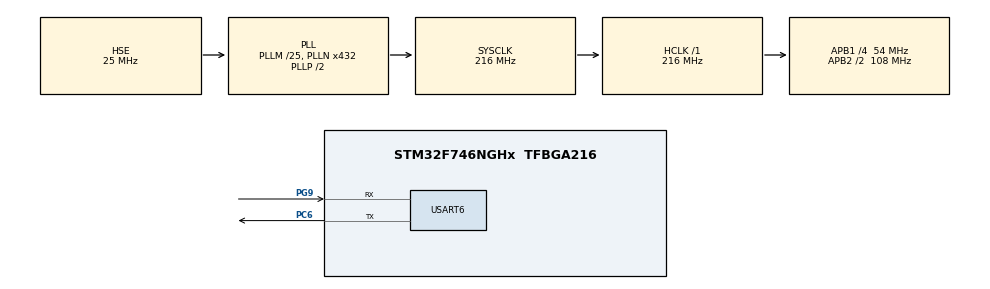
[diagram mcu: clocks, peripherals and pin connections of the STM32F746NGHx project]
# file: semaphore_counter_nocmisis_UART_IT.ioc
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FREERTOS.Tasks01=defaultTask,0,128,StartDefaultTask,Default,NULL,Dynamic,NULL,NULL
FREERTOS.configUSE_COUNTING_SEMAPHORES=1
Mcu.Family=STM32F7
Mcu.Name=STM32F746NGHx
Mcu.Package=TFBGA216
NVIC.PriorityGroup=NVIC_PRIORITYGROUP_4
NVIC.TIM1_UP_TIM10_IRQn=true\:15\:0\:false\:false\:true\:false\:false\:true\:true
NVIC.TimeBase=TIM1_UP_TIM10_IRQn
NVIC.TimeBaseIP=TIM1
NVIC.USART6_IRQn=true\:5\:0\:false\:false\:true\:true\:true\:true\:true
PC6.Mode=Asynchronous
PC6.Signal=USART6_TX
PG9.Mode=Asynchronous
PG9.Signal=USART6_RX
PH0/OSC_IN.Mode=HSE-External-Oscillator
PH0/OSC_IN.Signal=RCC_OSC_IN
PH1/OSC_OUT.Mode=HSE-External-Oscillator
PH1/OSC_OUT.Signal=RCC_OSC_OUT
ProjectManager.HeapSize=0x200
ProjectManager.StackSize=0x400
ProjectManager.TargetToolchain=STM32CubeIDE
RCC.AHBFreq_Value=216000000
RCC.APB1CLKDivider=RCC_HCLK_DIV4
RCC.APB1Freq_Value=54000000
RCC.APB1TimFreq_Value=108000000
RCC.APB2CLKDivider=RCC_HCLK_DIV2
RCC.APB2Freq_Value=108000000
RCC.APB2TimFreq_Value=216000000
RCC.CortexFreq_Value=216000000
RCC.HCLKFreq_Value=216000000
RCC.HSE_VALUE=25000000
RCC.HSI_VALUE=16000000
RCC.PLL48CLockSelection=RCC_CLK48SOURCE_PLLSAIP
RCC.PLLI2SN=100
RCC.PLLM=25
RCC.PLLN=432
RCC.PLLQ=9
RCC.PLLSAIN=384
RCC.PLLSAIP=RCC_PLLSAIP_DIV8
RCC.PLLSAIR=5
RCC.PLLSAIRDiv=RCC_PLLSAIDIVR_8
RCC.PLLSourceVirtual=RCC_PLLSOURCE_HSE
RCC.SDMMCClockSelection=RCC_SDMMC1CLKSOURCE_CLK48
RCC.SYSCLKFreq_VALUE=216000000
RCC.SYSCLKSource=RCC_SYSCLKSOURCE_PLLCLK
RCC.USBFreq_Value=48000000
RCC.VCOOutputFreq_Value=432000000
USART6.VirtualMode-Asynchronous=VM_ASYNC
VP_FREERTOS_VS_CMSIS_V1.Mode=CMSIS_V1
VP_SYS_VS_tim1.Mode=TIM1
board=STM32F746G-DISCO

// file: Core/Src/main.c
/* USER CODE BEGIN Header */
/**
  ******************************************************************************
  * @file           : main.c
  * @brief          : Main program body
  ******************************************************************************
  * @attention
  *
  * Copyright (c) 2025 STMicroelectronics.
  * All rights reserved.
  *
  * This software is licensed under terms that can be found in the LICENSE file
  * in the root directory of this software component.
  * If no LICENSE file comes with this software, it is provided AS-IS.
  *
  ******************************************************************************
  */
/* USER CODE END Header */
#include "main.h"
//YT: ControllersTech
//Binary semaphore needs to be released by the task that hase acquired it, where as counting semaphore can be released anywhere
//#include "cmsis_os.h" <---------------------------------not used
/*| Prefix | Meaning                                    | Example                                 |
  | ------ | ------------------------------------------ | --------------------------------------- |
  | `x`    | **BaseType\_t** (int32\_t or int)          | `xTaskCreate()`, `xSemaphoreGive()`     |
  | `v`    | **void** return type                       | `vTaskDelay()`, `vTaskStartScheduler()` |
  | `pd`   | **Port-dependent value** (usually boolean) | `pdTRUE`, `pdFALSE`                     |
  | `ux`   | **Unsigned BaseType\_t**                   | `uxTaskPriorityGet()`                   |
  | `pv`   | **Pointer to void**                        | `pvPortMalloc()`                        |
  | `e`    | **Enum**                                   | `eRunning`, `eBlocked`                  |
 *
 *Many functions like xSemaphoreTake() or xQueueSend() return a status (pdTRUE or pdFALSE), and the x implies it's returning a BaseType_t, not void.
 *It’s a reminder to the developer: check the return value.
 *
 * */
/* USER CODE BEGIN Includes */
#include "FreeRTOS.h" //includes are from cmsis file: common microcomputer software interface standardftware
#include "task.h"
#include "timers.h"
#include "queue.h"
#include "semphr.h"
#include "event_groups.h"

#include "stdlib.h"
#include "string.h"
/* USER CODE END Includes */

UART_HandleTypeDef huart6;

void SystemClock_Config(void);
static void MX_GPIO_Init(void);
static void MX_USART6_UART_Init(void);

/* USER CODE BEGIN 0 */

//create task defines

TaskHandle_t HPThandler;
void HPT_TASK(void *pvParamaters);

TaskHandle_t MPThandler;
void MPT_TASK(void *pvParamaters);

TaskHandle_t LPThandler;
void LPT_TASK(void *pvParamaters);

TaskHandle_t VLPThandler;
void VLPT_TASK(void *pvParamaters);

//semaphore related
SemaphoreHandle_t CountingSem;

//resource related
int resource[3]= {111, 222, 333};
int indx = 0;

//uart related
uint8_t rx_data = 0;
/* USER CODE END 0 */

int main(void)
{

  /* MCU Configuration--------------------------------------------------------*/

  /* Reset of all peripherals, Initializes the Flash interface and the Systick. */
  HAL_Init();

  /* Configure the system clock */
  SystemClock_Config();

  /* Initialize all configured peripherals */
  MX_GPIO_Init();
  MX_USART6_UART_Init();
  /* USER CODE BEGIN 2 */
  HAL_UART_Receive_IT(&huart6, &rx_data, 1);
  CountingSem= xSemaphoreCreateCounting(3,0);
  if(CountingSem == NULL) HAL_UART_Transmit(&huart6, (uint8_t *) "Unable to create Semaphore \n \n ", 28, 100);
  else
  {
	  HAL_UART_Transmit(&huart6, (uint8_t *) "Counting Semaphore created successfully\n \n" , 41, 1000);
  }

  //create tasks
  xTaskCreate(HPT_TASK, "HPT", 128, NULL, 3, &HPThandler);
  xTaskCreate(MPT_TASK, "MPT", 128, NULL, 2, &MPThandler);
  xTaskCreate(LPT_TASK, "LPT", 128, NULL, 1, &LPThandler);
  xTaskCreate(VLPT_TASK,"VLPT",128, NULL, 0 , &VLPThandler);

  vTaskStartScheduler();
  /* USER CODE END 2 */

  /* We should never get here as control is now taken by the scheduler */

  /* Infinite loop */
  while (1)
  {

  }
}

void SystemClock_Config(void)
{
  RCC_OscInitTypeDef RCC_OscInitStruct = {0};
  RCC_ClkInitTypeDef RCC_ClkInitStruct = {0};

  /** Configure the main internal regulator output voltage
  */
  __HAL_RCC_PWR_CLK_ENABLE();
  __HAL_PWR_VOLTAGESCALING_CONFIG(PWR_REGULATOR_VOLTAGE_SCALE1);

  /** Initializes the RCC Oscillators according to the specified parameters
  * in the RCC_OscInitTypeDef structure.
  */
  RCC_OscInitStruct.OscillatorType = RCC_OSCILLATORTYPE_HSE;
  RCC_OscInitStruct.HSEState = RCC_HSE_ON;
  RCC_OscInitStruct.PLL.PLLState = RCC_PLL_ON;
  RCC_OscInitStruct.PLL.PLLSource = RCC_PLLSOURCE_HSE;
  RCC_OscInitStruct.PLL.PLLM = 25;
  RCC_OscInitStruct.PLL.PLLN = 432;
  RCC_OscInitStruct.PLL.PLLP = RCC_PLLP_DIV2;
  RCC_OscInitStruct.PLL.PLLQ = 9;
  if (HAL_RCC_OscConfig(&RCC_OscInitStruct) != HAL_OK)
  {
    Error_Handler();
  }

  /** Activate the Over-Drive mode
  */
  if (HAL_PWREx_EnableOverDrive() != HAL_OK)
  {
    Error_Handler();
  }

  /** Initializes the CPU, AHB and APB buses clocks
  */
  RCC_ClkInitStruct.ClockType = RCC_CLOCKTYPE_HCLK|RCC_CLOCKTYPE_SYSCLK
                              |RCC_CLOCKTYPE_PCLK1|RCC_CLOCKTYPE_PCLK2;
  RCC_ClkInitStruct.SYSCLKSource = RCC_SYSCLKSOURCE_PLLCLK;
  RCC_ClkInitStruct.AHBCLKDivider = RCC_SYSCLK_DIV1;
  RCC_ClkInitStruct.APB1CLKDivider = RCC_HCLK_DIV4;
  RCC_ClkInitStruct.APB2CLKDivider = RCC_HCLK_DIV2;

  if (HAL_RCC_ClockConfig(&RCC_ClkInitStruct, FLASH_LATENCY_7) != HAL_OK)
  {
    Error_Handler();
  }
}

static void MX_USART6_UART_Init(void)
{

  huart6.Instance = USART6;
  huart6.Init.BaudRate = 115200;
  huart6.Init.WordLength = UART_WORDLENGTH_8B;
  huart6.Init.StopBits = UART_STOPBITS_1;
  huart6.Init.Parity = UART_PARITY_NONE;
  huart6.Init.Mode = UART_MODE_TX_RX;
  huart6.Init.HwFlowCtl = UART_HWCONTROL_NONE;
  huart6.Init.OverSampling = UART_OVERSAMPLING_16;
  huart6.Init.OneBitSampling = UART_ONE_BIT_SAMPLE_DISABLE;
  huart6.AdvancedInit.AdvFeatureInit = UART_ADVFEATURE_NO_INIT;
  if (HAL_UART_Init(&huart6) != HAL_OK)
  {
    Error_Handler();
  }

}

static void MX_GPIO_Init(void)
{

  /* GPIO Ports Clock Enable */
  __HAL_RCC_GPIOG_CLK_ENABLE();
  __HAL_RCC_GPIOH_CLK_ENABLE();
  __HAL_RCC_GPIOC_CLK_ENABLE();

}

/* USER CODE BEGIN 4 */
void HPT_TASK ( void *pvParameters)
{
	char sresource[5];
	int semcount=0;
	char ssemcount[5];
	//Give 3 Semaphores at the beginning
	/*semaphores can be released in any part of the code*/
	xSemaphoreGive(CountingSem);
	xSemaphoreGive(CountingSem);
	xSemaphoreGive(CountingSem);

	while(1)
	{
		char str[300];
		strcpy(str, "\rEntered HPT Task\r\nAbout to ACQUIRE the semaphore\r\n\n");
		semcount = uxSemaphoreGetCount(CountingSem);
		itoa(semcount, ssemcount, 10);
		strcat(str, "Tokens available are: ");
		strcat(str, ssemcount);
		//strcat(str, "\n\n");
        HAL_UART_Transmit(&huart6, (uint8_t *)str, strlen(str), HAL_MAX_DELAY);

        // Acquire semaphore
        xSemaphoreTake(CountingSem, portMAX_DELAY);

        // Prepare second message
		itoa(resource[indx], sresource, 10);
		strcpy(str, "\r\nLeaving HPT Task\r\nData ACCESSED :: ");
		strcat(str, sresource);
		strcat(str, "\r\nNot releasing the Semaphore\r\n\n");

		HAL_UART_Transmit(&huart6, (uint8_t *)str, strlen(str), HAL_MAX_DELAY);

		indx++;
		if(indx>2) indx=0;
//		vTaskDelay(3000);
		vTaskDelete(NULL);
	}
}

void MPT_TASK ( void *pvParameters)
{
	char sresource[3];
	int semcount=0;
	char ssemcount[2];
	while(1)
	{
		char str[300];
		strcpy(str, "\r\nEntered MPT Task\r\nAbout to ACQUIRE the semaphore\r\n\n");
		semcount = uxSemaphoreGetCount(CountingSem);
		itoa(semcount, ssemcount, 10);
		strcat(str, "Tokens available are: ");
		strcat(str, ssemcount);
		//strcat(str, "\n\n");
		HAL_UART_Transmit(&huart6, (uint8_t *)str, strlen(str), HAL_MAX_DELAY);
		xSemaphoreTake(CountingSem, portMAX_DELAY);
		itoa(resource[indx], sresource, 10);
		strcpy(str, "\r\nLeaving MPT Task\n\rData ACCCESSED :: ");
		strcat(str, sresource);
		strcat(str, "\r\nNot releasing the Semaphore\r\n\n\n");
		HAL_UART_Transmit(&huart6, (uint8_t *)str, strlen(str), HAL_MAX_DELAY);

		indx++;
		if(indx>2) indx=0;
//		vTaskDelay(2000);
		vTaskDelete(NULL);
	}
}

void LPT_TASK ( void *pvParameters)
{
	char sresource[3];
	int semcount=0;
	char ssemcount[2];
	while(1)
	{
		char str[150];
		strcpy(str, "\r\nEntered LPT Task\r\nAbout to ACQUIRE the semaphore\r\n");
		semcount = uxSemaphoreGetCount(CountingSem);
		itoa(semcount, ssemcount, 10);
		strcat(str, "Tokens available are: ");
		strcat(str, ssemcount);
		//strcat(str, "\n\n");

		HAL_UART_Transmit(&huart6, (uint8_t *)str, strlen(str), HAL_MAX_DELAY);
		xSemaphoreTake(CountingSem, portMAX_DELAY);
		itoa(resource[indx], sresource, 10);
		strcpy(str, "\r\nLeaving LPT Task\r\n Data ACCCESSED :: ");
		strcat(str, sresource);
		strcat(str, "\r\nNot releasing the Semaphore\r\n\n\n");
		HAL_UART_Transmit(&huart6, (uint8_t *)str, strlen(str), HAL_MAX_DELAY);

		indx++;
		if(indx>2) indx=0;
//		vTaskDelay(1000);
		vTaskDelete(NULL);
	}
}

void VLPT_TASK ( void *pvParameters)
{
	char sresource[3];
	int semcount=0;
	char ssemcount[2];
	while(1)
	{
		char str[300];
		strcpy(str, "\r\nEntered VLPT Task\r\nAbout to ACQUIRE the semaphore\r\n\n");
		semcount = uxSemaphoreGetCount(CountingSem);
		itoa(semcount, ssemcount, 10);
		strcat(str, "Tokens available are: ");
		strcat(str, ssemcount);
		//strcat(str, "\n\n");

		HAL_UART_Transmit(&huart6, (uint8_t *)str, strlen(str), HAL_MAX_DELAY);
		xSemaphoreTake(CountingSem, portMAX_DELAY);
		itoa(resource[indx], sresource, 10);
		strcpy(str, "\r\nLeaving VLPT Task\nData ACCCESSED :: ");
		strcat(str, sresource);
		strcat(str, "\r\nNot releasing the Semaphore\r\n\n\n");
		HAL_UART_Transmit(&huart6, (uint8_t *)str, strlen(str), HAL_MAX_DELAY);
		indx++;
		if(indx>2) indx=0;
		vTaskDelay(500);

	}
}

void HAL_UART_RxCpltCallback(UART_HandleTypeDef *huart)
{
	HAL_UART_Receive_IT(huart, &rx_data, 1);
	if(rx_data == 'r')
	{
		//release semaphore data here
		/*The xHigherPriorityTaskWoken parameter must be initialized to pdFALSE as it will
		 * get set to pdTRUE inside the interrupt safe API function if a context switch is required*/
		BaseType_t xHigherPriorityTaskWoken = pdFALSE;
		xSemaphoreGiveFromISR(CountingSem, & xHigherPriorityTaskWoken); //ISR SAFE VERSION

		/*Pass the xHigherPriorityTaskWoken value into portEND_SWITCH_ISR(). If
		 xHigherPriorityTaskWoken was set to pdTRUE inside xSemaphoreGiveFromISR()
		 then calling portEND_SWITCHING_ISR() will have no effect*/

		portEND_SWITCHING_ISR(xHigherPriorityTaskWoken);
	}
}
/* USER CODE END 4 */

void HAL_TIM_PeriodElapsedCallback(TIM_HandleTypeDef *htim)
{
  if (htim->Instance == TIM1)
  {
    HAL_IncTick();
  }
}

void Error_Handler(void)
{
  __disable_irq();
  while (1)
  {
  }
}

//
///* USER CODE BEGIN Header */
///**
//  ******************************************************************************
//  * @file           : main.c
//  * @brief          : Main program body
//  ******************************************************************************
//  * @attention
//  *
//  * Copyright (c) 2025 STMicroelectronics.
//  * All rights reserved.
//  *
//  * This software is licensed under terms that can be found in the LICENSE file
//  * in the root directory of this software component.
//  * If no LICENSE file comes with this software, it is provided AS-IS.
//  *
//  ******************************************************************************
//  */
///* USER CODE END Header */
///* Includes ------------------------------------------------------------------*/
//#include "main.h"
////YT: ControllersTech
////#include "cmsis_os.h" <---------------------------------not used
///*| Prefix | Meaning                                    | Example                                 |
//  | ------ | ------------------------------------------ | --------------------------------------- |
//  | `x`    | **BaseType\_t** (int32\_t or int)          | `xTaskCreate()`, `xSemaphoreGive()`     |
//  | `v`    | **void** return type                       | `vTaskDelay()`, `vTaskStartScheduler()` |
//  | `pd`   | **Port-dependent value** (usually boolean) | `pdTRUE`, `pdFALSE`                     |
//  | `ux`   | **Unsigned BaseType\_t**                   | `uxTaskPriorityGet()`                   |
//  | `pv`   | **Pointer to void**                        | `pvPortMalloc()`                        |
//  | `e`    | **Enum**                                   | `eRunning`, `eBlocked`                  |
// *
// *Many functions like xSemaphoreTake() or xQueueSend() return a status (pdTRUE or pdFALSE), and the x implies it's returning a BaseType_t, not void.
// *It’s a reminder to the developer: check the return value.
// *
// * */
///* Private includes ----------------------------------------------------------*/
///* USER CODE BEGIN Includes */
//#include "FreeRTOS.h" //includes are from cmsis file: common microcomputer software interface standardftware
//#include "task.h"
//#include "timers.h"
//#include "queue.h"
//#include "semphr.h"
//#include "event_groups.h"
//
//
//#include "stdlib.h"
//#include "string.h"
///* USER CODE END Includes */
//
///* Private typedef -----------------------------------------------------------*/
///* USER CODE BEGIN PTD */
//
///* USER CODE END PTD */
//
///* Private define ------------------------------------------------------------*/
///* USER CODE BEGIN PD */
//
///* USER CODE END PD */
//
///* Private macro -------------------------------------------------------------*/
///* USER CODE BEGIN PM */
//
///* USER CODE END PM */
//
///* Private variables ---------------------------------------------------------*/
//
//UART_HandleTypeDef huart6;
//
///* USER CODE BEGIN PV */
//
///* USER CODE END PV */
//
///* Private function prototypes -----------------------------------------------*/
//void SystemClock_Config(void);
//static void MX_GPIO_Init(void);
//static void MX_USART6_UART_Init(void);
//
//
///* USER CODE BEGIN PFP */
//
///* USER CODE END PFP */
//
///* Private user code ---------------------------------------------------------*/
///* USER CODE BEGIN 0 */
//
////create task defines
//
//TaskHandle_t HPThandler;
//void HPT_TASK(void *pvParamaters);
//
//TaskHandle_t MPThandler;
//void MPT_TASK(void *pvParamaters);
//
//TaskHandle_t LPThandler;
//void LPT_TASK(void *pvParamaters);
//
//TaskHandle_t VLPThandler;
//void VLPT_TASK(void *pvParamaters);
//
////semaphore related
//SemaphoreHandle_t CountingSem;
//
////resource related
//int resource[3]= {111, 222, 333};
//int indx = 0;
//
////uart related
//uint8_t rx_data = 0;
///* USER CODE END 0 */
//
///**
//  * @brief  The application entry point.
//  * @retval int
//  */
//int main(void)
//{
//
//  /* USER CODE BEGIN 1 */
//
//  /* USER CODE END 1 */
//
//  /* MCU Configuration--------------------------------------------------------*/
//
//  /* Reset of all peripherals, Initializes the Flash interface and the Systick. */
//  HAL_Init();
//
//  /* USER CODE BEGIN Init */
//
//  /* USER CODE END Init */
//
//  /* Configure the system clock */
//  SystemClock_Config();
//
//  /* USER CODE BEGIN SysInit */
//
//  /* USER CODE END SysInit */
//
//  /* Initialize all configured peripherals */
//  MX_GPIO_Init();
//  MX_USART6_UART_Init();
//  /* USER CODE BEGIN 2 */
//  HAL_UART_Receive_IT(&huart6, &rx_data, 1);
//  CountingSem= xSemaphoreCreateCounting(3,0);
//  if(CountingSem == NULL) HAL_UART_Transmit(&huart6, (uint8_t *) "Unable to create Semaphore \n \n ", 28, 100);
//  else
//  {
//	  HAL_UART_Transmit(&huart6, (uint8_t *) "\r\nCounting Semaphore created successfully" , 41, 1000);
//  }
//
//  //create tasks
//  xTaskCreate(HPT_TASK, "HPT", 128, NULL, 3, &HPThandler);
//  xTaskCreate(MPT_TASK, "MPT", 128, NULL, 2, &MPThandler);
//  xTaskCreate(LPT_TASK, "LPT", 128, NULL, 1, &LPThandler);
//  xTaskCreate(VLPT_TASK,"VLPT",128, NULL, 0 , &VLPThandler);
//
//  vTaskStartScheduler();
//  /* USER CODE END 2 */
//
//
//
//
//  /* We should never get here as control is now taken by the scheduler */
//
//  /* Infinite loop */
//  /* USER CODE BEGIN WHILE */
//  while (1)
//  {
//    /* USER CODE END WHILE */
//
//    /* USER CODE BEGIN 3 */
//  }
//  /* USER CODE END 3 */
//}
//
///**
//  * @brief System Clock Configuration
//  * @retval None
//  */
//void SystemClock_Config(void)
//{
//  RCC_OscInitTypeDef RCC_OscInitStruct = {0};
//  RCC_ClkInitTypeDef RCC_ClkInitStruct = {0};
//
//  /** Configure the main internal regulator output voltage
//  */
//  __HAL_RCC_PWR_CLK_ENABLE();
//  __HAL_PWR_VOLTAGESCALING_CONFIG(PWR_REGULATOR_VOLTAGE_SCALE1);
//
//  /** Initializes the RCC Oscillators according to the specified parameters
//  * in the RCC_OscInitTypeDef structure.
//  */
//  RCC_OscInitStruct.OscillatorType = RCC_OSCILLATORTYPE_HSE;
//  RCC_OscInitStruct.HSEState = RCC_HSE_ON;
//  RCC_OscInitStruct.PLL.PLLState = RCC_PLL_ON;
//  RCC_OscInitStruct.PLL.PLLSource = RCC_PLLSOURCE_HSE;
//  RCC_OscInitStruct.PLL.PLLM = 25;
//  RCC_OscInitStruct.PLL.PLLN = 432;
//  RCC_OscInitStruct.PLL.PLLP = RCC_PLLP_DIV2;
//  RCC_OscInitStruct.PLL.PLLQ = 9;
//  if (HAL_RCC_OscConfig(&RCC_OscInitStruct) != HAL_OK)
//  {
//    Error_Handler();
//  }
//
//  /** Activate the Over-Drive mode
//  */
//  if (HAL_PWREx_EnableOverDrive() != HAL_OK)
//  {
//    Error_Handler();
//  }
//
//  /** Initializes the CPU, AHB and APB buses clocks
//  */
//  RCC_ClkInitStruct.ClockType = RCC_CLOCKTYPE_HCLK|RCC_CLOCKTYPE_SYSCLK
//                              |RCC_CLOCKTYPE_PCLK1|RCC_CLOCKTYPE_PCLK2;
//  RCC_ClkInitStruct.SYSCLKSource = RCC_SYSCLKSOURCE_PLLCLK;
//  RCC_ClkInitStruct.AHBCLKDivider = RCC_SYSCLK_DIV1;
//  RCC_ClkInitStruct.APB1CLKDivider = RCC_HCLK_DIV4;
//  RCC_ClkInitStruct.APB2CLKDivider = RCC_HCLK_DIV2;
//
//  if (HAL_RCC_ClockConfig(&RCC_ClkInitStruct, FLASH_LATENCY_7) != HAL_OK)
//  {
//    Error_Handler();
//  }
//}
//
///**
//  * @brief USART6 Initialization Function
//  * @param None
//  * @retval None
//  */
//static void MX_USART6_UART_Init(void)
//{
//
//  /* USER CODE BEGIN USART6_Init 0 */
//
//  /* USER CODE END USART6_Init 0 */
//
//  /* USER CODE BEGIN USART6_Init 1 */
//
//  /* USER CODE END USART6_Init 1 */
//  huart6.Instance = USART6;
//  huart6.Init.BaudRate = 115200;
//  huart6.Init.WordLength = UART_WORDLENGTH_8B;
//  huart6.Init.StopBits = UART_STOPBITS_1;
//  huart6.Init.Parity = UART_PARITY_NONE;
//  huart6.Init.Mode = UART_MODE_TX_RX;
//  huart6.Init.HwFlowCtl = UART_HWCONTROL_NONE;
//  huart6.Init.OverSampling = UART_OVERSAMPLING_16;
//  huart6.Init.OneBitSampling = UART_ONE_BIT_SAMPLE_DISABLE;
//  huart6.AdvancedInit.AdvFeatureInit = UART_ADVFEATURE_NO_INIT;
//  if (HAL_UART_Init(&huart6) != HAL_OK)
//  {
//    Error_Handler();
//  }
//  /* USER CODE BEGIN USART6_Init 2 */
//
//  /* USER CODE END USART6_Init 2 */
//
//}
//
///**
//  * @brief GPIO Initialization Function
//  * @param None
//  * @retval None
//  */
//static void MX_GPIO_Init(void)
//{
//  /* USER CODE BEGIN MX_GPIO_Init_1 */
//
//  /* USER CODE END MX_GPIO_Init_1 */
//
//  /* GPIO Ports Clock Enable */
//  __HAL_RCC_GPIOG_CLK_ENABLE();
//  __HAL_RCC_GPIOH_CLK_ENABLE();
//  __HAL_RCC_GPIOC_CLK_ENABLE();
//
//  /* USER CODE BEGIN MX_GPIO_Init_2 */
//
//  /* USER CODE END MX_GPIO_Init_2 */
//}
//
///* USER CODE BEGIN 4 */
//void HPT_TASK ( void *pvParameters)
//{
//	char sresource[5];
//	int semcount=0;
//	char ssemcount[5];
//	//Give 3 Semaphores at the beginning
//	/*semaphores can be released in any part of the code*/
//	xSemaphoreGive(CountingSem);
//	xSemaphoreGive(CountingSem);
//	xSemaphoreGive(CountingSem);
//
//	while(1)
//	{
//		char str[300];
//		strcpy(str, "\r\nEntered HPT Task\r\nAbout to ACQUIRE the semaphore");
//				semcount = uxSemaphoreGetCount(CountingSem);
//				itoa(semcount, ssemcount, 10);
//				strcat(str, "\r\nTokens available are: \n");
//				strcat(str, ssemcount);
//
//		        HAL_UART_Transmit(&huart6, (uint8_t *)str, strlen(str), HAL_MAX_DELAY);
//
//		        // Acquire semaphore
//		        xSemaphoreTake(CountingSem, portMAX_DELAY);
//
//		        // Prepare second message
//		        itoa(resource[indx], sresource, 10);
//		        strcpy(str, "\r\nLeaving HPT Task\r\nData ACCESSED :: ");
//		        strcat(str, sresource);
//		        strcat(str, "\r\nNot releasing the Semaphore\r\n\r\n");
//
//		        HAL_UART_Transmit(&huart6, (uint8_t *)str, strlen(str), HAL_MAX_DELAY);
//
//		        indx++;
//		if(indx>2) indx=0;
////		vTaskDelay(3000);
//		vTaskDelete(NULL);
//	}
//}
//
//void MPT_TASK ( void *pvParameters)
//{
//	char sresource[3];
//	int semcount=0;
//	char ssemcount[2];
//	while(1)
//	{
//		char str[300];
//		strcpy(str, "\rEntered MPT Task\r\nAbout to ACQUIRE the semaphore");
//		semcount = uxSemaphoreGetCount(CountingSem);
//		itoa(semcount, ssemcount, 10);
//		strcat(str, "\r\nTokens available are: \n");
//		strcat(str, ssemcount);
//
//		HAL_UART_Transmit(&huart6, (uint8_t *)str, strlen(str), HAL_MAX_DELAY);
//		xSemaphoreTake(CountingSem, portMAX_DELAY);
//		itoa(resource[indx], sresource, 10);
//		strcpy(str, "\r\nLeaving MPT Task\n\rData ACCCESSED :: ");
//		strcat(str, sresource);
//		strcat(str, "\r\nNot releasing the Semaphore\r\n\n\n");
//		HAL_UART_Transmit(&huart6, (uint8_t *)str, strlen(str), HAL_MAX_DELAY);
//
//		indx++;
//		if(indx>2) indx=0;
////		vTaskDelay(2000);
//		vTaskDelete(NULL);
//	}
//}
//
//void LPT_TASK ( void *pvParameters)
//{
//	char sresource[3];
//	int semcount=0;
//	char ssemcount[2];
//	while(1)
//	{
//		char str[150];
//		strcpy(str, "\rEntered LPT Task\r\nAbout to ACQUIRE the semaphore");
//		semcount = uxSemaphoreGetCount(CountingSem);
//		itoa(semcount, ssemcount, 10);
//		strcat(str, "\r\nTokens available are: \n");
//		strcat(str, ssemcount);
//
//		HAL_UART_Transmit(&huart6, (uint8_t *)str, strlen(str), HAL_MAX_DELAY);
//		xSemaphoreTake(CountingSem, portMAX_DELAY);
//		itoa(resource[indx], sresource, 10);
//		strcpy(str, "\r\nLeaving LPT Task\r\n Data ACCCESSED :: ");
//		strcat(str, sresource);
//		strcat(str, "\r\nNot releasing the Semaphore\r\n\n\n");
//		HAL_UART_Transmit(&huart6, (uint8_t *)str, strlen(str), HAL_MAX_DELAY);
//
//		indx++;
//		if(indx>2) indx=0;
////		vTaskDelay(1000);
//		vTaskDelete(NULL);
//	}
//}
//
//void VLPT_TASK ( void *pvParameters)
//{
//	char sresource[3];
//	int semcount=0;
//	char ssemcount[2];
//	while(1)
//	{
//		char str[300];
//		strcpy(str, "\rEntered VLPT Task\r\nAbout to ACQUIRE the semaphore");
//		semcount = uxSemaphoreGetCount(CountingSem);
//		itoa(semcount, ssemcount, 10);
//		strcat(str, "\r\nTokens available are: \n");
//		strcat(str, ssemcount);
//
//		HAL_UART_Transmit(&huart6, (uint8_t *)str, strlen(str), HAL_MAX_DELAY);
//		xSemaphoreTake(CountingSem, portMAX_DELAY);
//		itoa(resource[indx], sresource, 10);
//		strcpy(str, "\r\nLeaving VLPT Task\nData ACCCESSED :: ");
//		strcat(str, sresource);
//		strcat(str, "\r\nNot releasing the Semaphore\r\n\n\n");
//		HAL_UART_Transmit(&huart6, (uint8_t *)str, strlen(str), HAL_MAX_DELAY);
//		indx++;
//		if(indx>2) indx=0;
////		vTaskDelay(500);
//		vTaskDelete(NULL);
//	}
//}
//
//void HAL_UART_RxCpltCallback(UART_HandleTypeDef *huart)
//{
//	HAL_UART_Receive_IT(huart, &rx_data, 1);
//	if(rx_data == 'r')
//	{
//		//release semaphore data here
//		/*The xHigherPriorityTaskWoken parameter must be initialized to pdFALSE as it will
//		 * get set to pdTRUE inside the interrupt safe API function if a context switch is required*/
//		BaseType_t xHigherPriorityTaskWoken = pdFALSE;
//		xSemaphoreGiveFromISR(CountingSem, & xHigherPriorityTaskWoken); //ISR SAFE VERSION
//
//		/*Pass the xHigherPriorityTaskWoken value into portEND_SWITCH_ISR(). If
//		 xHigherPriorityTaskWoken was set to pdTRUE inside xSemaphoreGiveFromISR()
//		 then calling portEND_SWITCHING_ISR() will have no effect*/
//
//		portEND_SWITCHING_ISR(xHigherPriorityTaskWoken);
//	}
//}
///* USER CODE END 4 */
//
//
///**
//  * @brief  Period elapsed callback in non blocking mode
//  * @note   This function is called  when TIM1 interrupt took place, inside
//  * HAL_TIM_IRQHandler(). It makes a direct call to HAL_IncTick() to increment
//  * a global variable "uwTick" used as application time base.
//  * @param  htim : TIM handle
//  * @retval None
//  */
//void HAL_TIM_PeriodElapsedCallback(TIM_HandleTypeDef *htim)
//{
//  /* USER CODE BEGIN Callback 0 */
//
//  /* USER CODE END Callback 0 */
//  if (htim->Instance == TIM1)
//  {
//    HAL_IncTick();
//  }
//  /* USER CODE BEGIN Callback 1 */
//
//  /* USER CODE END Callback 1 */
//}
//
///**
//  * @brief  This function is executed in case of error occurrence.
//  * @retval None
//  */
//void Error_Handler(void)
//{
//  /* USER CODE BEGIN Error_Handler_Debug */
//  /* User can add his own implementation to report the HAL error return state */
//  __disable_irq();
//  while (1)
//  {
//  }
//  /* USER CODE END Error_Handler_Debug */
//}
//
//#ifdef  USE_FULL_ASSERT
///**
//  * @brief  Reports the name of the source file and the source line number
//  *         where the assert_param error has occurred.
//  * @param  file: pointer to the source file name
//  * @param  line: assert_param error line source number
//  * @retval None
//  */
//void assert_failed(uint8_t *file, uint32_t line)
//{
//  /* USER CODE BEGIN 6 */
//  /* User can add his own implementation to report the file name and line number,
//     ex: printf("Wrong parameters value: file %s on line %d\r\n", file, line) */
//  /* USER CODE END 6 */
//}
//#endif /* USE_FULL_ASSERT */
//
//
//
//
//
